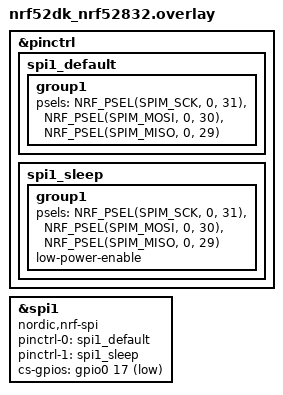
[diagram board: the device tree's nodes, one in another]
&pinctrl {
	spi1_default: spi1_default {
		group1 {
			psels = <NRF_PSEL(SPIM_SCK, 0, 31)>,
					<NRF_PSEL(SPIM_MOSI, 0, 30)>,
					<NRF_PSEL(SPIM_MISO, 0, 29)>;
		};
	};

	spi1_sleep: spi1_sleep {
		group1 {
			psels = <NRF_PSEL(SPIM_SCK, 0, 31)>,
					<NRF_PSEL(SPIM_MOSI, 0, 30)>,
					<NRF_PSEL(SPIM_MISO, 0, 29)>;
			low-power-enable;
		};
	};
};

&spi1 {
	compatible = "nordic,nrf-spi";
	status = "okay";
	pinctrl-0 = <&spi1_default>;
	pinctrl-1 = <&spi1_sleep>;
	cs-gpios = <&gpio0 17 GPIO_ACTIVE_LOW>;
};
